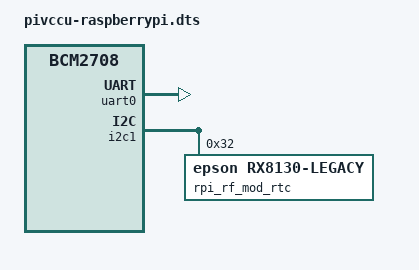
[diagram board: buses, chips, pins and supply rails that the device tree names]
/dts-v1/;
/plugin/;

/ {
  compatible = "brcm,bcm2708";

  fragment@0 {
    target = <&uart0>;
    __overlay__ {
      compatible = "pivccu,pl011";
      status = "okay";
      pivccu,reset-gpios = <&gpio 18 0>, <&gpio 19 0>;
      pivccu,led-gpios = <&gpio 16 0>, <&gpio 20 0>, <&gpio 21 0>;
      pivccu,rtc = <&rpi_rf_mod_rtc>;
    };
  };

  fragment@1 {
    target = <&i2c1>;
    __overlay__ {
      #address-cells = <1>;
      #size-cells = <0>;
      status = "okay";

      rpi_rf_mod_rtc: rx8130@32 {
        compatible = "epson,rx8130-legacy";
        reg = <0x32>;
        status = "okay";
        aux-voltage-chargeable = <1>;
        enable-external-capacitor;
      };
    };
  };
};

